# apollo2 register map
Vendor: Ambiq Micro, Inc.; Series: Apollo; File version: 1.0
CPU: CM4 r1p0, little endian, MPU, FPU, 3 interrupt priority bits
Registers are 32-bit, read-write, reset 0x0 unless marked. A register's access mark holds for its fields unless they carry their own. Offsets are from the block's base; [hi:lo] are bit positions.

## MCUCTRL — MCU Miscellaneous Control Logic
Base 0x40020000
0x00 CHIP_INFO reset 0x3000000 — Chip Information Register
  [31:0] PARTNUM — BCD part number.
    0x3000000=APOLLO2 (Apollo2 part number is 0x03XXXXXX.); 0x1000000=APOLLO (Apollo part number is 0x01XXXXXX.); 0xFF000000=PN_M (Mask for the PN field.)
0x04 CHIPID0 — Unique Chip ID 0
  [31:0] VALUE — Unique chip ID 0.
    0=APOLLO2 (Apollo2 CHIPID0. The lower 32-bits of the 64-bit CHIPID value, which is unique for each part.)
0x08 CHIPID1 — Unique Chip ID 1
  [31:0] VALUE — Unique chip ID 1.
    0=APOLLO2 (Apollo2 CHIPID1. The upper 32-bits of the 64-bit CHIPID value, which is unique for each part.)
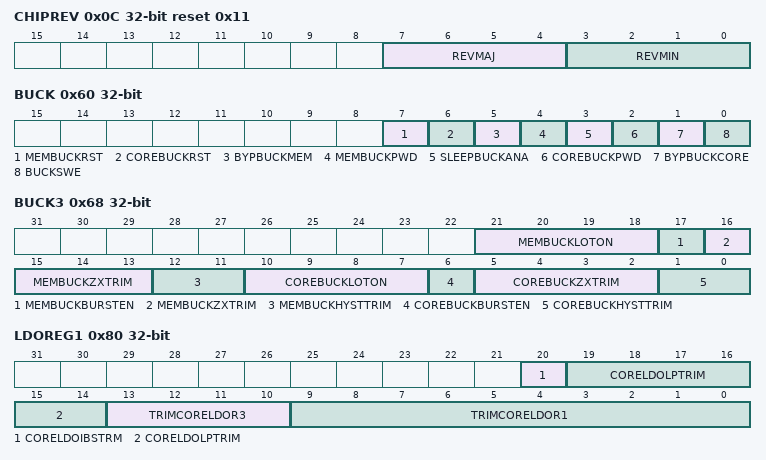
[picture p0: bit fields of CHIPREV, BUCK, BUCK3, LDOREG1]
0x0C CHIPREV reset 0x11 — Chip Revision
  [7:4] REVMAJ — Major Revision ID.
    2=B (Apollo2 revision B); 1=A (Apollo2 revision A)
  [3:0] REVMIN — Minor Revision ID.
    0=REV0 (Apollo2 minor revision value. Succeeding minor revisions will increment from this value.); 2=REV2 (Apollo2 minor revision value.)
0x10 VENDORID — Unique Vendor ID
  [31:0] VALUE
    0x414D4251=AMBIQ (Ambiq Vendor ID)
0x14 DEBUGGER — Debugger Access Control
  [0] LOCKOUT — Lockout of debugger (SWD).
0x60 BUCK — Analog Buck Control
  [7] MEMBUCKRST — Reset control override for Mem Buck; 0=enabled, 1=reset; Value is propagated only when the BUCKSWE bit is active, otherwise contrl is from the power control module.
  [6] COREBUCKRST — Reset control override for Core Buck; 0=enabled, 1=reset; Value is propagated only when the BUCKSWE bit is active, otherwise control is from the power control module.
  [5] BYPBUCKMEM — Not used. Additional control of buck is available in the power control module
  [4] MEMBUCKPWD — Memory buck power down override. 1=Powered Down; 0=Enabled; Value is propagated only when the BUCKSWE bit is active, otherwise control is from the power control module.
    0=EN (Memory Buck Enable.)
  [3] SLEEPBUCKANA — HFRC clkgen bit 0 override. When set, this will override to 0 bit 0 of the hfrc_freq_clkgen internal bus (see internal Shelby-1473)
  [2] COREBUCKPWD — Core buck power down override. 1=Powered Down; 0=Enabled; Value is propagated only when the BUCKSWE bit is active, otherwise control is from the power control module.
    0=EN (Core Buck enable.)
  [1] BYPBUCKCORE — Not used. Additional control of buck is available in the power control module
  [0] BUCKSWE — Buck Register Software Override Enable. This will enable the override values for MEMBUCKPWD, COREBUCKPWD, COREBUCKRST, MEMBUCKRST, all to be propagated to the control logic, instead of the normal power control module signal. Note - Must take care to have correct value for ALL the register bits when this SWE is enabled.
    0=OVERRIDE_DIS (BUCK Software Override Disable.); 1=OVERRIDE_EN (BUCK Software Override Enable.)
0x68 BUCK3 — Buck control reg 3
  [21:18] MEMBUCKLOTON — MEM Buck low TON trim value
  [17] MEMBUCKBURSTEN — MEM Buck burst enable 0=disable, 0=disabled, 1=enable.
  [16:13] MEMBUCKZXTRIM — Memory buck zero crossing trim value
  [12:11] MEMBUCKHYSTTRIM — Hysterisis trim for mem buck
  [10:7] COREBUCKLOTON — Core Buck low TON trim value
  [6] COREBUCKBURSTEN — Core Buck burst enable. 0=disabled, 1=enabled
  [5:2] COREBUCKZXTRIM — Core buck zero crossing trim value
  [1:0] COREBUCKHYSTTRIM — Hysterisis trim for core buck
0x80 LDOREG1 — Analog LDO Reg 1
  [20] CORELDOIBSTRM — CORE LDO IBIAS Trim
  [19:14] CORELDOLPTRIM — CORE LDO Low Power Trim
  [13:10] TRIMCORELDOR3 — CORE LDO tempco trim (R3).
  [9:0] TRIMCORELDOR1 — CORE LDO Active mode ouput trim (R1).
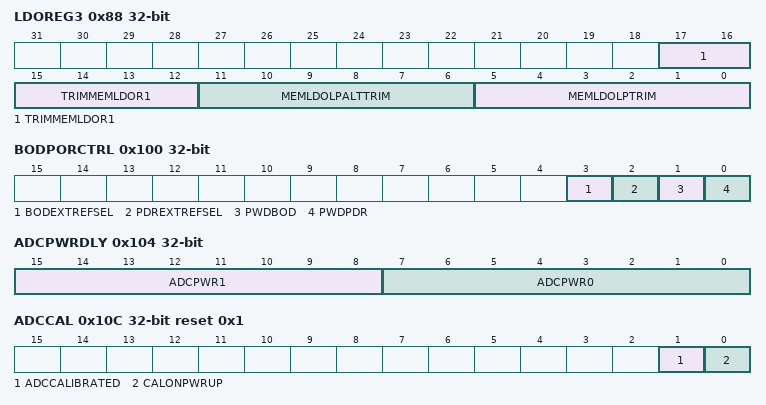
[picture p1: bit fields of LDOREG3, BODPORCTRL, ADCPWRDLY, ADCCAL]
0x88 LDOREG3 — LDO Control Register 3
  [17:12] TRIMMEMLDOR1 — MEM LDO active mode trim (R1).
  [11:6] MEMLDOLPALTTRIM — MEM LDO TRIM for low power mode with ADC active
  [5:0] MEMLDOLPTRIM — MEM LDO TRIM for low power mode with ADC inactive
0x100 BODPORCTRL — BOD and PDR control Register
  [3] BODEXTREFSEL — BOD External Reference Select.
    1=SELECT (BOD external reference select.)
  [2] PDREXTREFSEL — PDR External Reference Select.
    1=SELECT (PDR external reference select.)
  [1] PWDBOD — BOD Power Down.
    1=PWR_DN (BOD power down.)
  [0] PWDPDR — PDR Power Down.
    1=PWR_DN (PDR power down)
0x104 ADCPWRDLY — ADC Power Up Delay Control
  [15:8] ADCPWR1 — ADC Reference Keeper enable delay in 16 ADC CLK increments for ADC_CLKSEL = 0x1, 8 ADC CLOCK increments for ADC_CLKSEL = 0x2.
  [7:0] ADCPWR0 — ADC Reference Buffer Power Enable delay in 64 ADC CLK increments for ADC_CLKSEL = 0x1, 32 ADC CLOCK increments for ADC_CLKSEL = 0x2.
0x10C ADCCAL reset 0x1 — ADC Calibration Control
  [1] ADCCALIBRATED — Status for ADC Calibration
    0=FALSE (ADC is not calibrated); 1=TRUE (ADC is calibrated)
  [0] CALONPWRUP — Run ADC Calibration on initial power up sequence
    0=DIS (Disable automatic calibration on initial power up); 1=EN (Enable automatic calibration on initial power up)
0x110 ADCBATTLOAD — ADC Battery Load Enable
  [0] BATTLOAD — Enable the ADC battery load resistor
    0=DIS (Battery load is disconnected); 1=EN (Battery load is enabled)
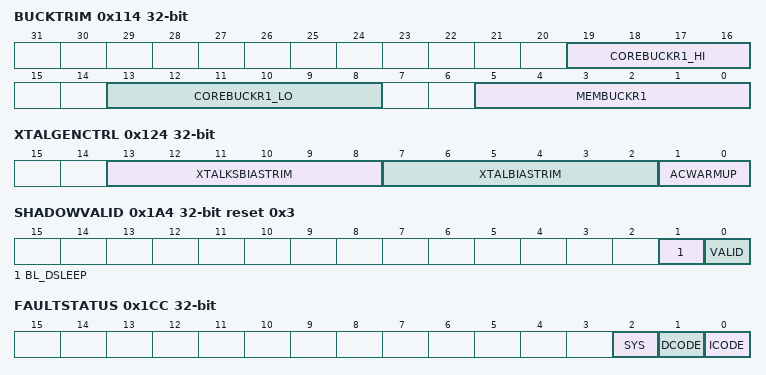
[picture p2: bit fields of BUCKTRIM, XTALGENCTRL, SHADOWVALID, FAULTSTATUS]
0x114 BUCKTRIM — Trim settings for Core and Mem buck modules
  [19:16] COREBUCKR1_HI — Core Buck voltage output trim bits[9:6]. Concatenate with field COREBUCKR1_LO for the full trim value.
  [13:8] COREBUCKR1_LO — Core Buck voltage output trim bits[5:0], Concatenate with field COREBUCKR1_HI for the full trim value.
  [5:0] MEMBUCKR1 — Trim values for BUCK regulator.
0x124 XTALGENCTRL — XTAL Oscillator General Control
  [13:8] XTALKSBIASTRIM — XTAL IBIAS Kick start trim . This trim value is used during the startup process to enable a faster lock and is applied when the kickstart signal is active.
  [7:2] XTALBIASTRIM — XTAL IBIAS trim
  [1:0] ACWARMUP — Auto-calibration delay control
    0=1SEC (Warmup period of 1-2 seconds); 1=2SEC (Warmup period of 2-4 seconds); 2=4SEC (Warmup period of 4-8 seconds); 3=8SEC (Warmup period of 8-16 seconds)
0x1A0 BOOTLOADERLOW reset 0x1 — Determines whether the bootloader code is visible at address 0x00000000
  [0] VALUE — Determines whether the bootloader code is visible at address 0x00000000 or not.
    1=ADDR0 (Bootloader code at 0x00000000.)
0x1A4 SHADOWVALID reset 0x3 — Register to indicate whether the shadow registers have been successfully loaded from the Flash Information Space.
  [1] BL_DSLEEP — Indicates whether the bootloader should sleep or deep sleep if no image loaded.
    1=DEEPSLEEP (Bootloader will go to deep sleep if no flash image loaded)
  [0] VALID — Indicates whether the shadow registers contain valid data from the Flash Information Space.
    1=VALID (Flash information space contains valid data.)
0x1C0 ICODEFAULTADDR — ICODE bus address which was present when a bus fault occurred.
  [31:0] ADDR — The ICODE bus address observed when a Bus Fault occurred. Once an address is captured in this field, it is held until the corresponding Fault Observed bit is cleared in the FAULTSTATUS register.
0x1C4 DCODEFAULTADDR — DCODE bus address which was present when a bus fault occurred.
  [31:0] ADDR — The DCODE bus address observed when a Bus Fault occurred. Once an address is captured in this field, it is held until the corresponding Fault Observed bit is cleared in the FAULTSTATUS register.
0x1C8 SYSFAULTADDR — System bus address which was present when a bus fault occurred.
  [31:0] ADDR — SYS bus address observed when a Bus Fault occurred. Once an address is captured in this field, it is held until the corresponding Fault Observed bit is cleared in the FAULTSTATUS register.
0x1CC FAULTSTATUS — Reflects the status of the bus decoders' fault detection. Any write to this register will clear all of the status bits within the register.
  [2] SYS — SYS Bus Decoder Fault Detected bit. When set, a fault has been detected, and the SYSFAULTADDR register will contain the bus address which generated the fault.
    0=NOFAULT (No bus fault has been detected.); 1=FAULT (Bus fault detected.)
  [1] DCODE — DCODE Bus Decoder Fault Detected bit. When set, a fault has been detected, and the DCODEFAULTADDR register will contain the bus address which generated the fault.
    0=NOFAULT (No DCODE fault has been detected.); 1=FAULT (DCODE fault detected.)
  [0] ICODE — The ICODE Bus Decoder Fault Detected bit. When set, a fault has been detected, and the ICODEFAULTADDR register will contain the bus address which generated the fault.
    0=NOFAULT (No ICODE fault has been detected.); 1=FAULT (ICODE fault detected.)
0x1D0 FAULTCAPTUREEN — Enable the fault capture registers
  [0] ENABLE — Fault Capture Enable field. When set, the Fault Capture monitors are enabled and addresses which generate a hard fault are captured into the FAULTADDR registers.
    0=DIS (Disable fault capture.); 1=EN (Enable fault capture.)
0x200 DBGR1 reset 0x12345678 — Read-only debug register 1
  [31:0] ONETO8 — Read-only register for communication validation
0x204 DBGR2 reset 0xC001C0DE — Read-only debug register 2
  [31:0] COOLCODE — Read-only register for communication validation
0x220 PMUENABLE reset 0x1 — Control bit to enable/disable the PMU
  [0] ENABLE — PMU Enable Control bit. When set, the MCU's PMU will place the MCU into the lowest power consuming Deep Sleep mode upon execution of a WFI instruction (dependent on the setting of the SLEEPDEEP bit in the ARM SCR register). When cleared, regardless of the requested sleep mode, the PMU will not enter the lowest power Deep Sleep mode, instead entering the Sleep mode.
    0=DIS (Disable MCU power management.); 1=EN (Enable MCU power management.)
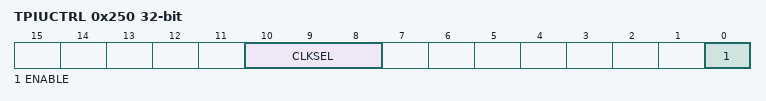
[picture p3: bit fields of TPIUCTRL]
0x250 TPIUCTRL — TPIU Control Register. Determines the clock enable and frequency for the M4's TPIU interface.
  [10:8] CLKSEL — This field selects the frequency of the ARM M4 TPIU port.
    0=LOW_PWR (Low power state.); 1=HFRC_DIV_2 (Selects HFRC divided by 2 as the source TPIU clk); 2=HFRC_DIV_8 (Selects HFRC divided by 8 as the source TPIU clk); 3=HFRC_DIV_16 (Selects HFRC divided by 16 as the source TPIU clk); 4=HFRC_DIV_32 (Selects HFRC divided by 32 as the source TPIU clk)
  [0] ENABLE — TPIU Enable field. When set, the ARM M4 TPIU is enabled and data can be streamed out of the MCU's SWO port using the ARM ITM and TPIU modules.
    0=DIS (Disable the TPIU.); 1=EN (Enable the TPIU.)
